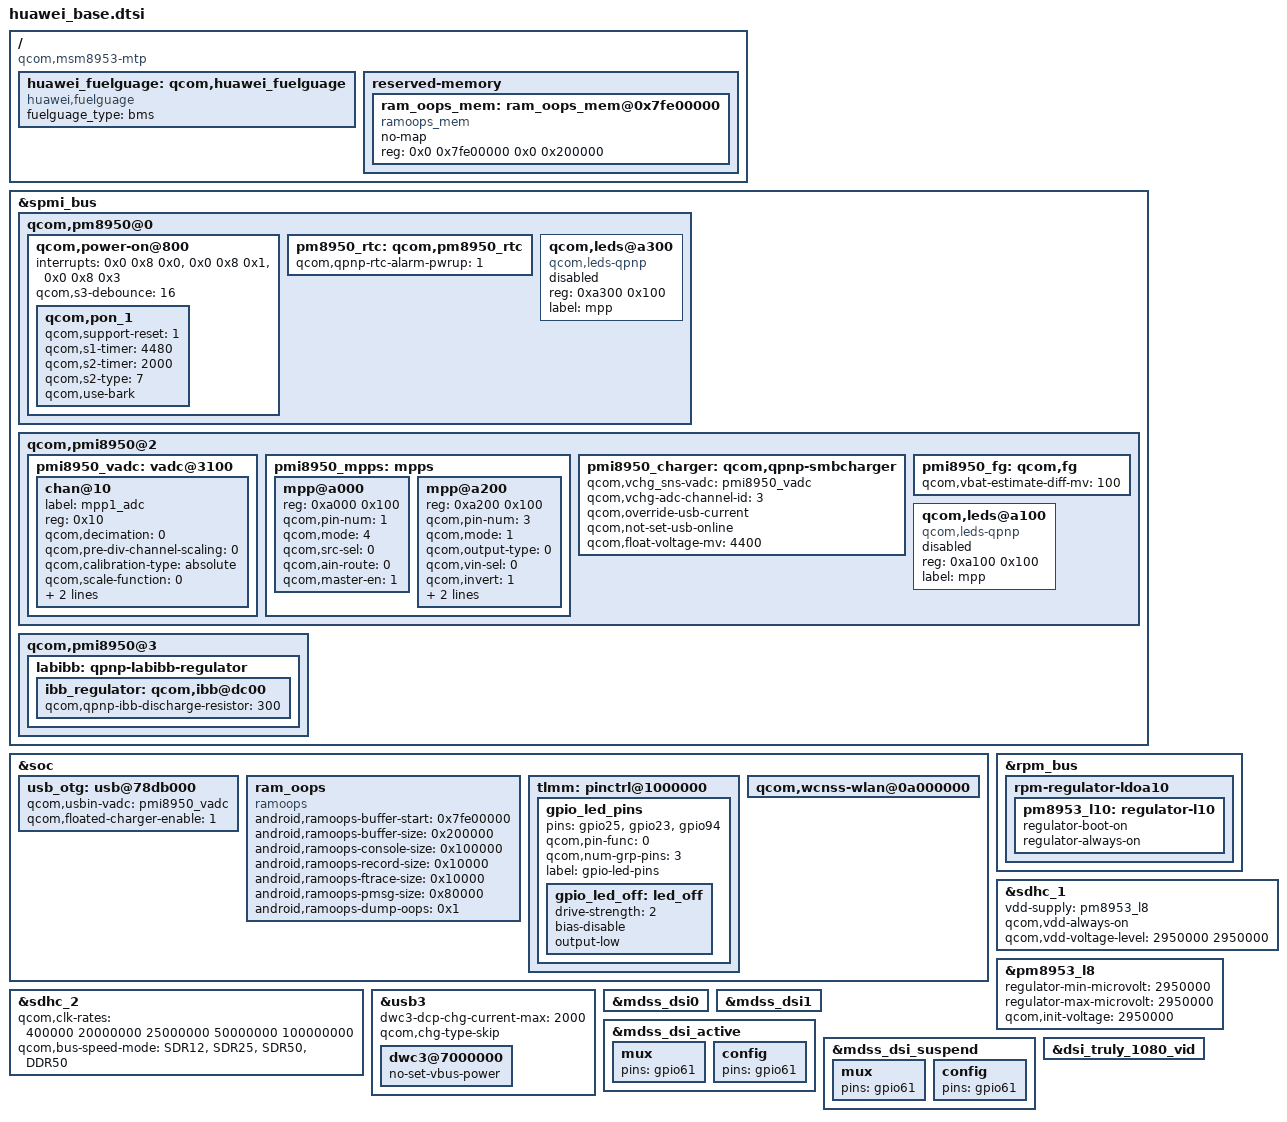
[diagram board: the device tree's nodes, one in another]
/*=============================================================================

                              Huawei Base Dtsi File

GENERAL DESCRIPTION
  This file is for include the Communal node

Copyright 2010-2014 by HUAWEI Technologies, Inc.  All Rights Reserved.
=============================================================================*/
#include "huawei_antenna_board_detect.dtsi"
#include "msm8953.dtsi"
#include "msm8953-mtp.dtsi"

/ {
	compatible = "qcom,msm8953-mtp", "qcom,msm8953", "qcom,mtp";
};

&spmi_bus {

	qcom,pm8950@0 {
		qcom,power-on@800 {
			interrupts = <0x0 0x8 0x0>,
				<0x0 0x8 0x1>,
				<0x0 0x8 0x3>;
			interrupt-names = "kpdpwr", "resin","kpdpwr-bark";
			qcom,s3-debounce = <16>;

			qcom,pon_1 {
				qcom,support-reset = <1>;
				qcom,s1-timer = <4480>;
				qcom,s2-timer = <2000>;
				qcom,s2-type = <7>;
				qcom,use-bark;
			};
		};

		pm8950_rtc: qcom,pm8950_rtc {
			qcom,qpnp-rtc-alarm-pwrup = <1>;
		};

		qcom,leds@a300 {
			compatible = "qcom,leds-qpnp";
			reg = <0xa300 0x100>;
			label = "mpp";
			status = "disabled";
		};
	};

	qcom,pmi8950@2 {
		pmi8950_vadc: vadc@3100 {
			chan@10 {
				label = "mpp1_adc";
				reg = <0x10>; // channel for MPP1
				qcom,decimation = <0>;
				qcom,pre-div-channel-scaling = <0>; //Use 1:1 scaling to keep input voltage with in Max voltage: 1.8V
				qcom,calibration-type = "absolute";
				qcom,scale-function = <0>;
				qcom,hw-settle-time = <1>;
				qcom,fast-avg-setup = <2>;
			};
		};

		pmi8950_mpps: mpps {
			mpp@a000 {
				reg = <0xa000 0x100>;
				qcom,pin-num = <1>;
				status = "ok";
				qcom,mode = <4>; // A-input
				qcom,src-sel = <0>; //MPP Constant
				qcom,ain-route = <0>; // QPNP_PIN_AIN_AMUX_CH5 = 0 for MPP1
				qcom,master-en = <1>; //Enable MPP
			};
			mpp@a200 {
				reg = <0xa200 0x100>;
				qcom,pin-num = <3>;
				qcom,mode = <1>;
				qcom,output-type = <0>;
				qcom,vin-sel = <0>;
				qcom,invert = <1>;
				qcom,src-sel = <0>;
				qcom,master-en = <1>;
				status = "okay";
			};
		};

		pmi8950_charger: qcom,qpnp-smbcharger {
			qcom,vchg_sns-vadc = <&pmi8950_vadc>;
			qcom,vchg-adc-channel-id = <3>;
			qcom,override-usb-current;
			qcom,not-set-usb-online;
			qcom,float-voltage-mv = <4400>;
		};

		pmi8950_fg: qcom,fg {
			qcom,vbat-estimate-diff-mv = <100>;
		};

		qcom,leds@a100 {
			compatible = "qcom,leds-qpnp";
			reg = <0xa100 0x100>;
			label = "mpp";
			status = "disabled";
		};
	};
	qcom,pmi8950@3 {
		labibb: qpnp-labibb-regulator {
			ibb_regulator: qcom,ibb@dc00 {
				qcom,qpnp-ibb-discharge-resistor = <300>;
			};
		};
	};
};

/{
	huawei_fuelguage: qcom,huawei_fuelguage{
		compatible = "huawei,fuelguage";
		fuelguage_type = "bms";
		status = "okay";
	};
};

&soc {
	usb_otg: usb@78db000 {
		qcom,usbin-vadc = <&pmi8950_vadc>;
		qcom,floated-charger-enable = <1>;
	};
};

/{
	reserved-memory {
		ram_oops_mem: ram_oops_mem@0x7fe00000 {
		   compatible = "ramoops_mem";
		   no-map;
		   reg = <0x0 0x7fe00000 0x0 0x200000>;
		 };
	};
};

&soc {
	 ram_oops {
		  compatible = "ramoops";
		  android,ramoops-buffer-start 	= <0x7fe00000>;
		  android,ramoops-buffer-size 	= <0x200000>;
		  android,ramoops-console-size 	= <0x100000>;
		  android,ramoops-record-size 	= <0x10000>;
		  android,ramoops-ftrace-size 	= <0x10000>;
		  android,ramoops-pmsg-size 	= <0x80000>;
		  android,ramoops-dump-oops 	= <0x1>;
	 };
};

&soc {
	tlmm: pinctrl@1000000 {
		gpio_led_pins {
			pins ="gpio25", "gpio23", "gpio94";
			qcom,pin-func = <0>;
			qcom,num-grp-pins = <3>;
			label = "gpio-led-pins";
			gpio_led_off: led_off {
				drive-strength = <2>;
				bias-disable;
				output-low;
			};
		};
	};
};

&rpm_bus {
	rpm-regulator-ldoa10 {
		pm8953_l10: regulator-l10 {
			regulator-boot-on;
			regulator-always-on;
		};
	};
};

&sdhc_1 {
	/* device core power supply */
	vdd-supply = <&pm8953_l8>;
	qcom,vdd-always-on;
	qcom,vdd-voltage-level = <2950000 2950000>;
};

&sdhc_2 {
	/* device core power supply */
	qcom,clk-rates = <400000 20000000 25000000 50000000 100000000>;
	qcom,bus-speed-mode = "SDR12", "SDR25", "SDR50", "DDR50";
};


&pm8953_l8 {
	regulator-min-microvolt = <2950000>;
	regulator-max-microvolt = <2950000>;
	qcom,init-voltage = <2950000>;
};

&usb3 {
	dwc3-dcp-chg-current-max = <2000>;
	qcom,chg-type-skip;
	dwc3@7000000 {
		no-set-vbus-power;
	};
};
&mdss_dsi0 {
	/delete-property/ qcom,platform-bklight-en-gpio;
	/delete-property/ vdd-supply;
};
&mdss_dsi1 {
	/delete-property/ vdd-supply;
};
&mdss_dsi_active {
	mux {
		pins = "gpio61";
	};
	config {
		pins = "gpio61";
	};
};

&mdss_dsi_suspend {
	mux {
		pins = "gpio61";
	};

	config {
		pins = "gpio61";
	};
};
&dsi_truly_1080_vid {
	/delete-property/ qcom,mdss-dsi-pan-enable-dynamic-fps;
	/delete-property/ qcom,mdss-dsi-pan-fps-update;
};

&soc {
	qcom,wcnss-wlan@0a000000 {
		/delete-property/ qcom,has-autodetect-xo;
	};
};
